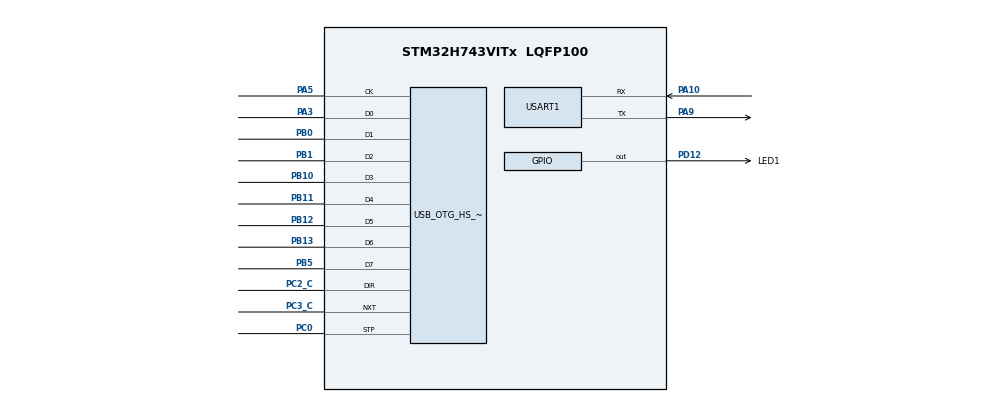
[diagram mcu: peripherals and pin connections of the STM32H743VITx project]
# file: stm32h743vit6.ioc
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CORTEX_M7.default_mode_Activation=1
Dma.Request0=USART1_RX
Dma.Request1=USART1_TX
Dma.USART1_RX.0.Direction=DMA_PERIPH_TO_MEMORY
Dma.USART1_RX.0.EventEnable=DISABLE
Dma.USART1_RX.0.FIFOMode=DMA_FIFOMODE_DISABLE
Dma.USART1_RX.0.Instance=DMA1_Stream0
Dma.USART1_RX.0.MemDataAlignment=DMA_MDATAALIGN_BYTE
Dma.USART1_RX.0.MemInc=DMA_MINC_ENABLE
Dma.USART1_RX.0.Mode=DMA_CIRCULAR
Dma.USART1_RX.0.PeriphDataAlignment=DMA_PDATAALIGN_BYTE
Dma.USART1_RX.0.PeriphInc=DMA_PINC_DISABLE
Dma.USART1_RX.0.Polarity=HAL_DMAMUX_REQ_GEN_RISING
Dma.USART1_RX.0.Priority=DMA_PRIORITY_LOW
Dma.USART1_RX.0.RequestNumber=1
Dma.USART1_RX.0.SignalID=NONE
Dma.USART1_RX.0.SyncEnable=DISABLE
Dma.USART1_RX.0.SyncPolarity=HAL_DMAMUX_SYNC_NO_EVENT
Dma.USART1_RX.0.SyncRequestNumber=1
Dma.USART1_RX.0.SyncSignalID=NONE
Dma.USART1_TX.1.Direction=DMA_MEMORY_TO_PERIPH
Dma.USART1_TX.1.EventEnable=DISABLE
Dma.USART1_TX.1.FIFOMode=DMA_FIFOMODE_DISABLE
Dma.USART1_TX.1.Instance=DMA1_Stream1
Dma.USART1_TX.1.MemDataAlignment=DMA_MDATAALIGN_BYTE
Dma.USART1_TX.1.MemInc=DMA_MINC_ENABLE
Dma.USART1_TX.1.Mode=DMA_NORMAL
Dma.USART1_TX.1.PeriphDataAlignment=DMA_PDATAALIGN_BYTE
Dma.USART1_TX.1.PeriphInc=DMA_PINC_DISABLE
Dma.USART1_TX.1.Polarity=HAL_DMAMUX_REQ_GEN_RISING
Dma.USART1_TX.1.Priority=DMA_PRIORITY_LOW
Dma.USART1_TX.1.RequestNumber=1
Dma.USART1_TX.1.SignalID=NONE
Dma.USART1_TX.1.SyncEnable=DISABLE
Dma.USART1_TX.1.SyncPolarity=HAL_DMAMUX_SYNC_NO_EVENT
Dma.USART1_TX.1.SyncRequestNumber=1
Dma.USART1_TX.1.SyncSignalID=NONE
Mcu.Family=STM32H7
Mcu.Name=STM32H743VITx
Mcu.Package=LQFP100
NVIC.DMA1_Stream0_IRQn=true\:0\:0\:false\:false\:true\:false\:true\:true
NVIC.DMA1_Stream1_IRQn=true\:0\:0\:false\:false\:true\:false\:true\:true
NVIC.OTG_HS_IRQn=true\:0\:0\:false\:false\:true\:false\:true\:true
NVIC.PriorityGroup=NVIC_PRIORITYGROUP_4
NVIC.USART1_IRQn=true\:0\:0\:false\:false\:true\:true\:true\:true
PA10.Mode=Asynchronous
PA10.Signal=USART1_RX
PA3.Mode=Device_HS
PA3.Signal=USB_OTG_HS_ULPI_D0
PA5.Mode=Device_HS
PA5.Signal=USB_OTG_HS_ULPI_CK
PA9.Mode=Asynchronous
PA9.Signal=USART1_TX
PB0.Mode=Device_HS
PB0.Signal=USB_OTG_HS_ULPI_D1
PB1.Mode=Device_HS
PB1.Signal=USB_OTG_HS_ULPI_D2
PB10.Mode=Device_HS
PB10.Signal=USB_OTG_HS_ULPI_D3
PB11.Mode=Device_HS
PB11.Signal=USB_OTG_HS_ULPI_D4
PB12.Mode=Device_HS
PB12.Signal=USB_OTG_HS_ULPI_D5
PB13.Mode=Device_HS
PB13.Signal=USB_OTG_HS_ULPI_D6
PB5.Mode=Device_HS
PB5.Signal=USB_OTG_HS_ULPI_D7
PC0.Mode=Device_HS
PC0.Signal=USB_OTG_HS_ULPI_STP
PC2_C.Mode=Device_HS
PC2_C.Signal=USB_OTG_HS_ULPI_DIR
PC3_C.Mode=Device_HS
PC3_C.Signal=USB_OTG_HS_ULPI_NXT
PD12.GPIO_Label=LED1
PD12.Signal=GPIO_Output
ProjectManager.HeapSize=0x200
ProjectManager.StackSize=0x400
ProjectManager.TargetToolchain=STM32CubeIDE
RCC.ADCFreq_Value=129000000
RCC.APB1Freq_Value=64000000
RCC.APB2Freq_Value=32000000
RCC.APB3Freq_Value=64000000
RCC.APB4Freq_Value=64000000
RCC.CortexFreq_Value=64000000
RCC.D2PPRE2=RCC_APB2_DIV2
RCC.HCLKFreq_Value=64000000
RCC.SYSCLKFreq_VALUE=64000000
RCC.USBCLockSelection=RCC_USBCLKSOURCE_HSI48
RCC.USBFreq_Value=48000000
USART1.VirtualMode-Asynchronous=VM_ASYNC
USB_DEVICE.CLASS_NAME_HS=CDC
USB_DEVICE.VirtualMode-CDC_HS=Cdc
USB_DEVICE.VirtualModeHS=Cdc_HS
USB_OTG_HS.VirtualMode-Device_HS=Device_HS
VP_MEMORYMAP_VS_MEMORYMAP.Mode=CurAppReg
VP_USB_DEVICE_VS_USB_DEVICE_CDC_HS.Mode=CDC_HS
board=custom

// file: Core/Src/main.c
/* USER CODE BEGIN Header */
/**
  ******************************************************************************
  * @file           : main.c
  * @brief          : Main program body
  ******************************************************************************
  * @attention
  *
  * Copyright (c) 2026 STMicroelectronics.
  * All rights reserved.
  *
  * This software is licensed under terms that can be found in the LICENSE file
  * in the root directory of this software component.
  * If no LICENSE file comes with this software, it is provided AS-IS.
  *
  ******************************************************************************
  */
/* USER CODE END Header */
#include "main.h"
#include "usb_device.h"

/* USER CODE BEGIN Includes */
#include "app_main.h"
#include "uart1_bridge.h"
/* USER CODE END Includes */

UART_HandleTypeDef huart1;
DMA_HandleTypeDef hdma_usart1_rx;
DMA_HandleTypeDef hdma_usart1_tx;

void SystemClock_Config(void);
static void MPU_Config(void);
static void MX_GPIO_Init(void);
static void MX_DMA_Init(void);
static void MX_USART1_UART_Init(void);

int main(void)
{

  /* MPU Configuration--------------------------------------------------------*/
  MPU_Config();

  /* MCU Configuration--------------------------------------------------------*/

  /* Reset of all peripherals, Initializes the Flash interface and the Systick. */
  HAL_Init();

  /* Configure the system clock */
  SystemClock_Config();

  /* Initialize all configured peripherals */
  MX_GPIO_Init();
  MX_DMA_Init();
  MX_USB_DEVICE_Init();
  MX_USART1_UART_Init();

  /* Infinite loop */
  /* USER CODE BEGIN WHILE */
  app_main();
  while (1)
  {
    /* USER CODE END WHILE */

  }
}

void SystemClock_Config(void)
{
  RCC_OscInitTypeDef RCC_OscInitStruct = {0};
  RCC_ClkInitTypeDef RCC_ClkInitStruct = {0};

  /** Supply configuration update enable
  */
  HAL_PWREx_ConfigSupply(PWR_LDO_SUPPLY);

  /** Configure the main internal regulator output voltage
  */
  __HAL_PWR_VOLTAGESCALING_CONFIG(PWR_REGULATOR_VOLTAGE_SCALE3);

  while(!__HAL_PWR_GET_FLAG(PWR_FLAG_VOSRDY)) {}

  /** Initializes the RCC Oscillators according to the specified parameters
  * in the RCC_OscInitTypeDef structure.
  */
  RCC_OscInitStruct.OscillatorType = RCC_OSCILLATORTYPE_HSI48|RCC_OSCILLATORTYPE_HSI;
  RCC_OscInitStruct.HSIState = RCC_HSI_DIV1;
  RCC_OscInitStruct.HSICalibrationValue = RCC_HSICALIBRATION_DEFAULT;
  RCC_OscInitStruct.HSI48State = RCC_HSI48_ON;
  RCC_OscInitStruct.PLL.PLLState = RCC_PLL_NONE;
  if (HAL_RCC_OscConfig(&RCC_OscInitStruct) != HAL_OK)
  {
    Error_Handler();
  }

  /** Initializes the CPU, AHB and APB buses clocks
  */
  RCC_ClkInitStruct.ClockType = RCC_CLOCKTYPE_HCLK|RCC_CLOCKTYPE_SYSCLK
                              |RCC_CLOCKTYPE_PCLK1|RCC_CLOCKTYPE_PCLK2
                              |RCC_CLOCKTYPE_D3PCLK1|RCC_CLOCKTYPE_D1PCLK1;
  RCC_ClkInitStruct.SYSCLKSource = RCC_SYSCLKSOURCE_HSI;
  RCC_ClkInitStruct.SYSCLKDivider = RCC_SYSCLK_DIV1;
  RCC_ClkInitStruct.AHBCLKDivider = RCC_HCLK_DIV1;
  RCC_ClkInitStruct.APB3CLKDivider = RCC_APB3_DIV1;
  RCC_ClkInitStruct.APB1CLKDivider = RCC_APB1_DIV1;
  RCC_ClkInitStruct.APB2CLKDivider = RCC_APB2_DIV2;
  RCC_ClkInitStruct.APB4CLKDivider = RCC_APB4_DIV1;

  if (HAL_RCC_ClockConfig(&RCC_ClkInitStruct, FLASH_LATENCY_1) != HAL_OK)
  {
    Error_Handler();
  }
}

static void MX_USART1_UART_Init(void)
{

  huart1.Instance = USART1;
  huart1.Init.BaudRate = 115200;
  huart1.Init.WordLength = UART_WORDLENGTH_8B;
  huart1.Init.StopBits = UART_STOPBITS_1;
  huart1.Init.Parity = UART_PARITY_NONE;
  huart1.Init.Mode = UART_MODE_TX_RX;
  huart1.Init.HwFlowCtl = UART_HWCONTROL_NONE;
  huart1.Init.OverSampling = UART_OVERSAMPLING_16;
  huart1.Init.OneBitSampling = UART_ONE_BIT_SAMPLE_DISABLE;
  huart1.Init.ClockPrescaler = UART_PRESCALER_DIV1;
  huart1.AdvancedInit.AdvFeatureInit = UART_ADVFEATURE_NO_INIT;
  if (HAL_UART_Init(&huart1) != HAL_OK)
  {
    Error_Handler();
  }
  if (HAL_UARTEx_SetTxFifoThreshold(&huart1, UART_TXFIFO_THRESHOLD_1_8) != HAL_OK)
  {
    Error_Handler();
  }
  if (HAL_UARTEx_SetRxFifoThreshold(&huart1, UART_RXFIFO_THRESHOLD_1_8) != HAL_OK)
  {
    Error_Handler();
  }
  if (HAL_UARTEx_DisableFifoMode(&huart1) != HAL_OK)
  {
    Error_Handler();
  }

}

static void MX_DMA_Init(void)
{

  /* DMA controller clock enable */
  __HAL_RCC_DMA1_CLK_ENABLE();

  /* DMA interrupt init */
  /* DMA1_Stream0_IRQn interrupt configuration */
  HAL_NVIC_SetPriority(DMA1_Stream0_IRQn, 0, 0);
  HAL_NVIC_EnableIRQ(DMA1_Stream0_IRQn);
  /* DMA1_Stream1_IRQn interrupt configuration */
  HAL_NVIC_SetPriority(DMA1_Stream1_IRQn, 0, 0);
  HAL_NVIC_EnableIRQ(DMA1_Stream1_IRQn);

}

static void MX_GPIO_Init(void)
{
  GPIO_InitTypeDef GPIO_InitStruct = {0};

  /* GPIO Ports Clock Enable */
  __HAL_RCC_GPIOC_CLK_ENABLE();
  __HAL_RCC_GPIOA_CLK_ENABLE();
  __HAL_RCC_GPIOB_CLK_ENABLE();
  __HAL_RCC_GPIOD_CLK_ENABLE();

  /*Configure GPIO pin Output Level */
  HAL_GPIO_WritePin(LED1_GPIO_Port, LED1_Pin, GPIO_PIN_RESET);

  /*Configure GPIO pin : LED1_Pin */
  GPIO_InitStruct.Pin = LED1_Pin;
  GPIO_InitStruct.Mode = GPIO_MODE_OUTPUT_PP;
  GPIO_InitStruct.Pull = GPIO_NOPULL;
  GPIO_InitStruct.Speed = GPIO_SPEED_FREQ_LOW;
  HAL_GPIO_Init(LED1_GPIO_Port, &GPIO_InitStruct);

}

/* USER CODE BEGIN 4 */
void HAL_UART_RxCpltCallback(UART_HandleTypeDef *huart)
{
    if (huart->Instance == USART1) uart1_on_rx_complete_isr();
}

void HAL_UART_TxCpltCallback(UART_HandleTypeDef *huart)
{
    if (huart->Instance == USART1) uart1_on_tx_complete_isr();
}

void HAL_UART_IdleCallback(UART_HandleTypeDef *huart)
{
    __HAL_UART_CLEAR_IDLEFLAG(huart);
    if (huart->Instance == USART1) uart1_on_rx_idle_isr();
}

void HAL_UART_ErrorCallback(UART_HandleTypeDef *huart)
{
    if (huart->Instance == USART1) uart1_on_error_isr();
}
/* USER CODE END 4 */

 /* MPU Configuration */

void MPU_Config(void)
{
  MPU_Region_InitTypeDef MPU_InitStruct = {0};

  /* Disables the MPU */
  HAL_MPU_Disable();

  /** Initializes and configures the Region and the memory to be protected
  */
  MPU_InitStruct.Enable = MPU_REGION_ENABLE;
  MPU_InitStruct.Number = MPU_REGION_NUMBER0;
  MPU_InitStruct.BaseAddress = 0x0;
  MPU_InitStruct.Size = MPU_REGION_SIZE_4GB;
  MPU_InitStruct.SubRegionDisable = 0x87;
  MPU_InitStruct.TypeExtField = MPU_TEX_LEVEL0;
  MPU_InitStruct.AccessPermission = MPU_REGION_NO_ACCESS;
  MPU_InitStruct.DisableExec = MPU_INSTRUCTION_ACCESS_DISABLE;
  MPU_InitStruct.IsShareable = MPU_ACCESS_SHAREABLE;
  MPU_InitStruct.IsCacheable = MPU_ACCESS_NOT_CACHEABLE;
  MPU_InitStruct.IsBufferable = MPU_ACCESS_NOT_BUFFERABLE;

  HAL_MPU_ConfigRegion(&MPU_InitStruct);
  /* Enables the MPU */
  HAL_MPU_Enable(MPU_PRIVILEGED_DEFAULT);

}

void Error_Handler(void)
{
  __disable_irq();
  while (1)
  {
  }
}
